# R7FA0E107 register map
Vendor: Renesas Electronics Corporation; Series: RA0; File version: 1.10.00
CPU: CM23 r1p0, little endian, no MPU, no FPU, VTOR, 2 interrupt priority bits, 64 interrupts
Registers are 16-bit, read-write, reset 0x0 unless marked. A register's access mark holds for its fields unless they carry their own. Offsets are from the block's base; [hi:lo] are bit positions.

## PCLBUZ — Clock Output/Buzzer Output Controller
Base 0x400A3B00
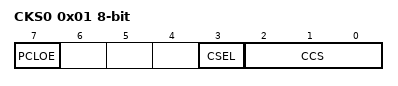
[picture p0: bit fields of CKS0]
0x01 CKS0 8-bit — Clock Out Control Register 0
  [7] PCLOE — Clock Out Enable
  [3] CSEL — Clock Out Select
  [2:0] CCS — Clock Out Divide Select

## TRNG — True Random Number Generator
Base 0x400D1000
0x00 TRNGSDR 8-bit ro — TRNG Seed Data Register
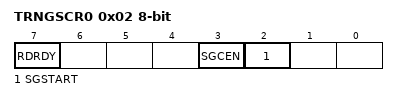
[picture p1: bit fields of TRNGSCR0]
0x02 TRNGSCR0 8-bit — TRNG Seed Command Register 0
  [7] RDRDY ro — Read Ready
  [3] SGCEN — Seed Generation Circuit Enable
  [2] SGSTART wo — Seed Generation Start
0x03 TRNGSCR1 8-bit — TRNG Seed Command Register 1
  [0] INTEN — TRNG Interrupt Enable

## FLCN — Flash I/O Registers
Base 0x407EC000
0x90 DFLCTL 8-bit — Data Flash Control Register
  [0] DFLEN — Data Flash Access Enable
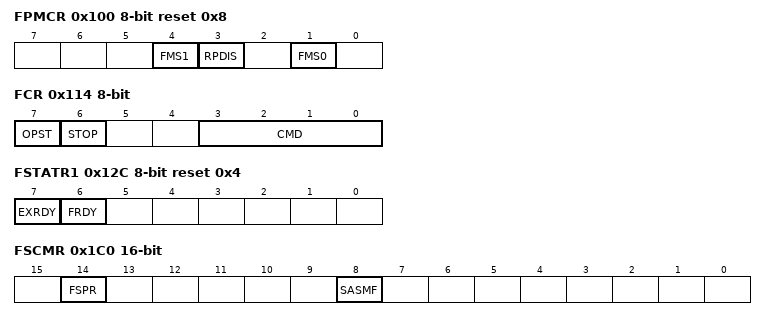
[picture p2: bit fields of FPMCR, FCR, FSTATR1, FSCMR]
0x100 FPMCR 8-bit reset 0x8 — Flash P/E Mode Control Register
  [4] FMS1 — Flash Operating Mode Select 1
  [3] RPDIS — Code Flash P/E Disable
  [1] FMS0 — Flash Operating Mode Select 0
0x104 FASR 8-bit — Flash Area Select Register
  [0] EXS — Extra Area Select
0x108 FSARL — Flash Processing Start Address Register L
  [15:0] FSARL — Flash Processing Start Address L
0x110 FSARH — Flash Processing Start Address Register H
  [15:0] FSARH — Flash Processing Start Address H
0x114 FCR 8-bit — Flash Control Register
  [7] OPST — Processing Start
  [6] STOP — Forced Processing Stop
  [3:0] CMD — Software Command Setting
0x118 FEARL — Flash Processing End Address Register L
  [15:0] FEARL — Flash Processing End Address L
0x120 FEARH — Flash Processing End Address Register H
  [15:0] FEARH — Flash Processing End Address H
0x124 FRESETR 8-bit — Flash Reset Register
  [0] FRESET — Software Reset of the Registers
0x12C FSTATR1 8-bit ro reset 0x4 — Flash Status Register 1
  [7] EXRDY — Extra Area Ready Flag
  [6] FRDY — Flash Ready Flag
0x130 FWBL0 — Flash Write Buffer Register L0
  [15:0] WDATA — Flash Write Buffer L0
0x138 FWBH0 — Flash Write Buffer Register H0
  [15:0] WDATA — Flash Write Buffer H0
0x180 FPR 8-bit wo reset not defined — Protection Unlock Register
  [7:0] FPR — Protection Unlock
0x184 FPSR 8-bit ro — Protection Unlock Status Register
  [0] PERR — Protect Error Flag
0x1C0 FSCMR ro (reset mask 0xBEFF) — Flash Startup Setting Monitor Register
  [14] FSPR — Access Window Protection Flag
  [8] SASMF — Startup Area Setting Monitor Flag
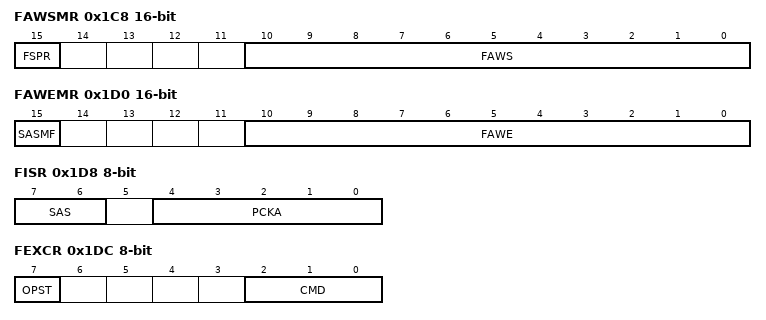
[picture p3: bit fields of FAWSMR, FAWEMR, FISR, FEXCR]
0x1C8 FAWSMR ro (reset mask 0x7800) — Flash Access Window Start Address Monitor Register
  [15] FSPR — Access Window Protection Flag
  [10:0] FAWS — Access Window Start Address
0x1D0 FAWEMR ro (reset mask 0x7800) — Flash Access Window End Address Monitor Register
  [15] SASMF — Startup Area Setting Monitor Flag
  [10:0] FAWE — Access Window End Address
0x1D8 FISR 8-bit — Flash Initial Setting Register
  [7:6] SAS — Startup Area Select
  [4:0] PCKA — Flash,IF Clock Notification
0x1DC FEXCR 8-bit — Flash Extra Area Control Register
  [7] OPST — Processing Start
  [2:0] CMD — Software Command Setting
0x1E0 FEAML ro — Flash Error Address Monitor Register L
0x1E8 FEAMH ro — Flash Error Address Monitor Register H
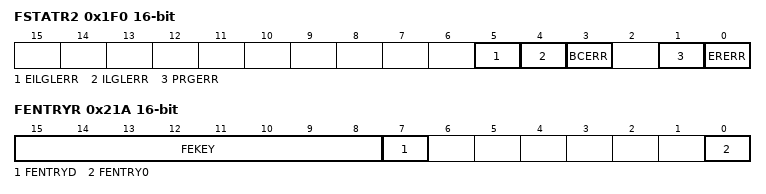
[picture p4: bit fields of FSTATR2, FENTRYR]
0x1F0 FSTATR2 ro — Flash Status Register 2
  [5] EILGLERR — Extra Area Illegal Command Error Flag
  [4] ILGLERR — Illegal Command Error Flag
  [3] BCERR — Blank Check Error Flag
  [1] PRGERR — Program Error Flag
  [0] ERERR — Erase Error Flag
0x200 HIOTRM 8-bit (reset mask 0xC0) — High,speed On,chip Oscillator Trimming Register
  [5:0] HIOTRM — HOCO User Trimming
0x20A FLMODE 8-bit reset 0x80 — Flash Operating Mode Control Register
  [7:6] MODE — Operating Mode Select
0x20B FLMWRP 8-bit — Flash Operating Mode Protect Register
  [0] FLMWEN — Control of Flash Operation Mode Select Register
0x21A FENTRYR — Flash P/E Mode Entry Register
  [15:8] FEKEY wo — Key Code
  [7] FENTRYD — Data Flash P/E Mode Entry
  [0] FENTRY0 — Code Flash P/E Mode Entry 0
